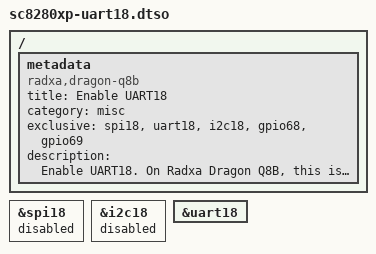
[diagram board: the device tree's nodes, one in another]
// SPDX-License-Identifier: BSD-3-Clause
/*
 * Copyright (c) 2026 Radxa Computer (Shenzhen) Co., Ltd.
 */

/dts-v1/;
/plugin/;

/ {
	metadata {
		title = "Enable UART18";
		compatible = "radxa,dragon-q8b";
		category = "misc";
		exclusive = "spi18", "uart18", "i2c18", "gpio68", "gpio69";
		description = "Enable UART18.
On Radxa Dragon Q8B, this is pin 16(tx), 37(rx).";
	};
};

&spi18 {
	status = "disabled";
};

&i2c18 {
	status = "disabled";
};

&uart18 {
	status = "okay";
};
